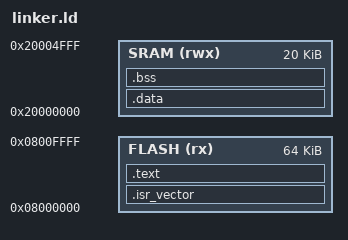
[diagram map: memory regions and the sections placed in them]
MEMORY
{
  FLASH (rx)  : ORIGIN = 0x08000000, LENGTH = 64K
  SRAM  (rwx) : ORIGIN = 0x20000000, LENGTH = 20K
}

/* Stack pointer = top of RAM */
_estack = ORIGIN(SRAM) + LENGTH(SRAM);

SECTIONS
{
  .isr_vector :
  {
    KEEP(*(.isr_vector))
  } > FLASH

  .text : {
    *(.text*)
    *(.rodata*)
  } > FLASH

  /* .data section */
  _sidata = LOADADDR(.data);

  .data : AT (ADDR(.text) + SIZEOF(.text))
  {
    _sdata = .;
    *(.data*)
    _edata = .;
  } > SRAM

  /* .bss section */
  .bss :
  {
    _sbss = .;
    *(.bss*)
    *(COMMON)
    _ebss = .;
  } > SRAM
}
